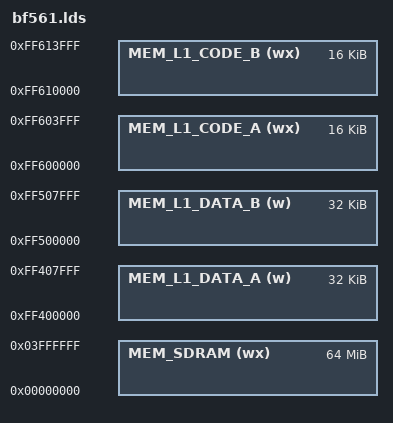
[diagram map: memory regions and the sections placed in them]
/*
** LDF for ADSP-BF561 Core B
*/

OUTPUT_ARCH(bfin)

MEMORY {
	MEM_SDRAM (wx)		: ORIGIN = 0x00000000, LENGTH = 64M

	MEM_L1_DATA_A (w)	: ORIGIN = 0xff400000, LENGTH = 32K
	MEM_L1_DATA_B (w)	: ORIGIN = 0xff500000, LENGTH = 32K
	MEM_L1_CODE_A (wx)	: ORIGIN = 0xff600000, LENGTH = 16K
	MEM_L1_CODE_B (wx)	: ORIGIN = 0xff610000, LENGTH = 16K
}
	
